# iostm32f205zx register map
Registers are 32-bit, access not given, no defined reset value unless marked. A register's access mark holds for its fields unless they carry their own. Addresses are absolute; registers are grouped by the start of their names; [hi:lo] are bit positions; {n}, {i} and the like mark numbered series; 'fields as' and 'values as' point back to an identical list.

## OTG
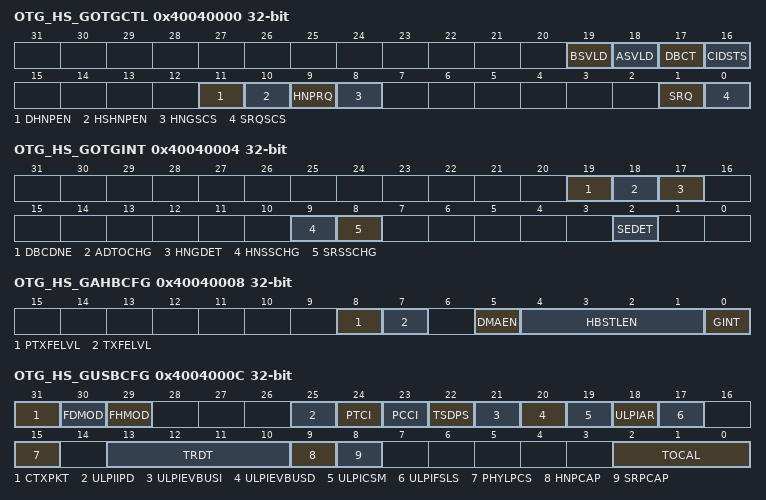
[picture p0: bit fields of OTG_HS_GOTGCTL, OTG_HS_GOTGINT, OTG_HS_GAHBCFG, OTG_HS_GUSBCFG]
0x40040000 OTG_HS_GOTGCTL
  [19] BSVLD, [18] ASVLD, [17] DBCT, [16] CIDSTS, [11] DHNPEN, [10] HSHNPEN, [9] HNPRQ, [8] HNGSCS, [1] SRQ, [0] SRQSCS
0x40040004 OTG_HS_GOTGINT
  [19] DBCDNE, [18] ADTOCHG, [17] HNGDET, [9] HNSSCHG, [8] SRSSCHG, [2] SEDET
0x40040008 OTG_HS_GAHBCFG
  [8] PTXFELVL, [7] TXFELVL, [5] DMAEN, [4:1] HBSTLEN, [0] GINT
0x4004000C OTG_HS_GUSBCFG
  [31] CTXPKT, [30] FDMOD, [29] FHMOD, [25] ULPIIPD, [24] PTCI, [23] PCCI, [22] TSDPS, [21] ULPIEVBUSI, [20] ULPIEVBUSD, [19] ULPICSM, [18] ULPIAR, [17] ULPIFSLS, [15] PHYLPCS, [13:10] TRDT, [9] HNPCAP, [8] SRPCAP, [2:0] TOCAL
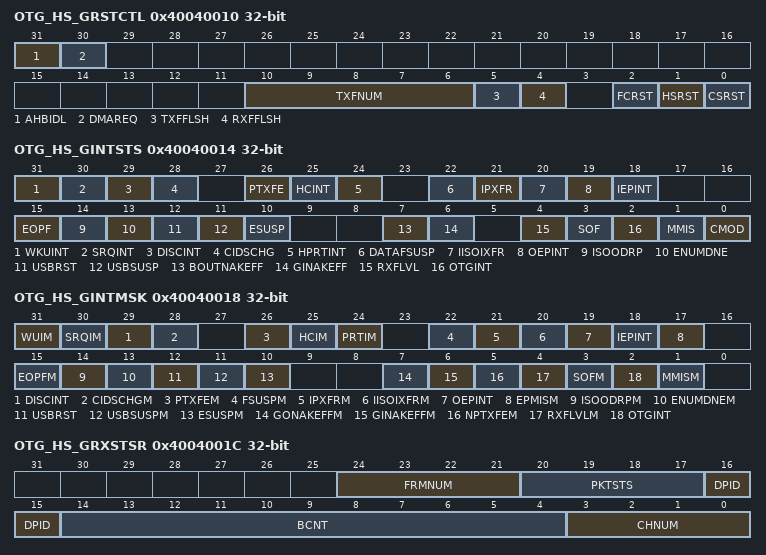
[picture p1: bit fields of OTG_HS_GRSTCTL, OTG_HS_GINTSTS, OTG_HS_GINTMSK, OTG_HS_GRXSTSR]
0x40040010 OTG_HS_GRSTCTL
  [31] AHBIDL, [30] DMAREQ, [10:6] TXFNUM, [5] TXFFLSH, [4] RXFFLSH, [2] FCRST, [1] HSRST, [0] CSRST
0x40040014 OTG_HS_GINTSTS
  [31] WKUINT, [30] SRQINT, [29] DISCINT, [28] CIDSCHG, [26] PTXFE, [25] HCINT, [24] HPRTINT, [22] DATAFSUSP, [21] IPXFR, [20] IISOIXFR, [19] OEPINT, [18] IEPINT, [15] EOPF, [14] ISOODRP, [13] ENUMDNE, [12] USBRST, [11] USBSUSP, [10] ESUSP, [7] BOUTNAKEFF, [6] GINAKEFF, [4] RXFLVL, [3] SOF, [2] OTGINT, [1] MMIS, [0] CMOD
0x40040018 OTG_HS_GINTMSK
  [31] WUIM, [30] SRQIM, [29] DISCINT, [28] CIDSCHGM, [26] PTXFEM, [25] HCIM, [24] PRTIM, [22] FSUSPM, [21] IPXFRM, [20] IISOIXFRM, [19] OEPINT, [18] IEPINT, [17] EPMISM, [15] EOPFM, [14] ISOODRPM, [13] ENUMDNEM, [12] USBRST, [11] USBSUSPM, [10] ESUSPM, [7] GONAKEFFM, [6] GINAKEFFM, [5] NPTXFEM, [4] RXFLVLM, [3] SOFM, [2] OTGINT, [1] MMISM
0x4004001C OTG_HS_GRXSTSR
  [24:21] FRMNUM, [20:17] PKTSTS, [16:15] DPID, [14:4] BCNT, [3:0] CHNUM
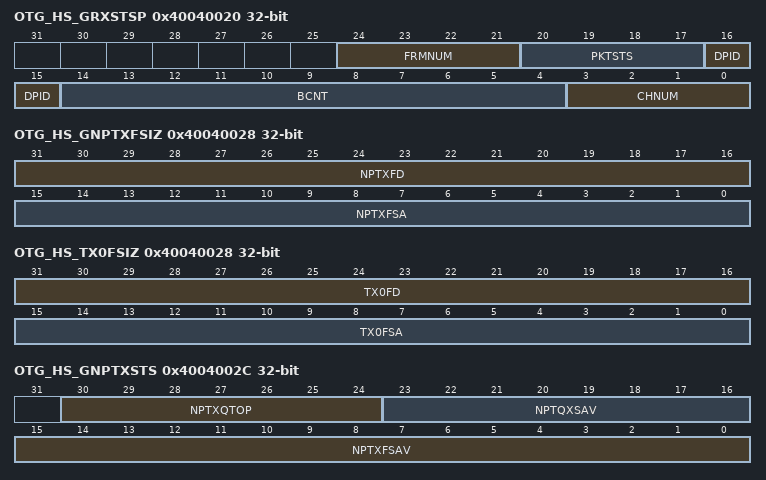
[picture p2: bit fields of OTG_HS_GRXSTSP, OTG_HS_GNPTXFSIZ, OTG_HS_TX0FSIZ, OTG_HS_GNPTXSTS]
0x40040020 OTG_HS_GRXSTSP
  fields as OTG_HS_GRXSTSR
0x40040024 OTG_HS_GRXFSIZ
  [15:0] RXFD
0x40040028 OTG_HS_GNPTXFSIZ
  [31:16] NPTXFD, [15:0] NPTXFSA
0x40040028 OTG_HS_TX0FSIZ
  [31:16] TX0FD, [15:0] TX0FSA
0x4004002C OTG_HS_GNPTXSTS
  [30:24] NPTXQTOP, [23:16] NPTQXSAV, [15:0] NPTXFSAV
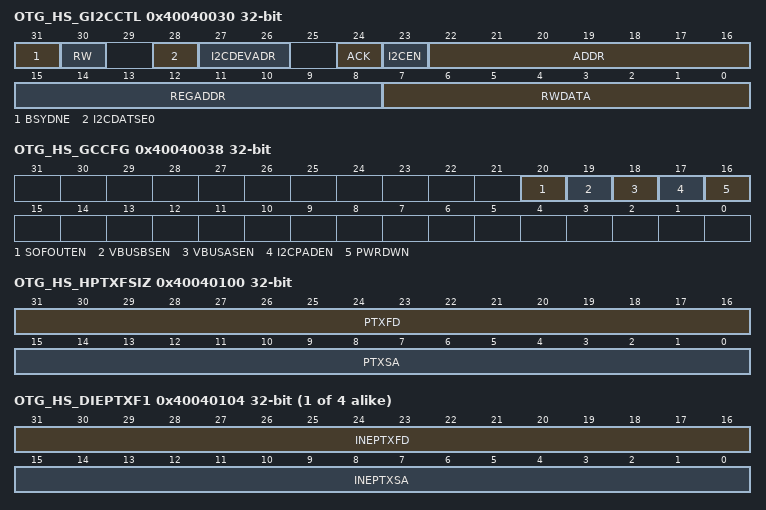
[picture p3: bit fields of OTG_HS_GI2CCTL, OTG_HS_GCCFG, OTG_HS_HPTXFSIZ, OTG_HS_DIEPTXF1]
0x40040030 OTG_HS_GI2CCTL
  [31] BSYDNE, [30] RW, [28] I2CDATSE0, [27:26] I2CDEVADR, [24] ACK, [23] I2CEN, [22:16] ADDR, [15:8] REGADDR, [7:0] RWDATA
0x40040038 OTG_HS_GCCFG
  [20] SOFOUTEN, [19] VBUSBSEN, [18] VBUSASEN, [17] I2CPADEN, [16] PWRDWN
0x4004003C OTG_HS_CID
0x40040100 OTG_HS_HPTXFSIZ
  [31:16] PTXFD, [15:0] PTXSA
{0x40040100+4i} OTG_HS_DIEPTXF{i} (i=1..4)
  [31:16] INEPTXFD, [15:0] INEPTXSA
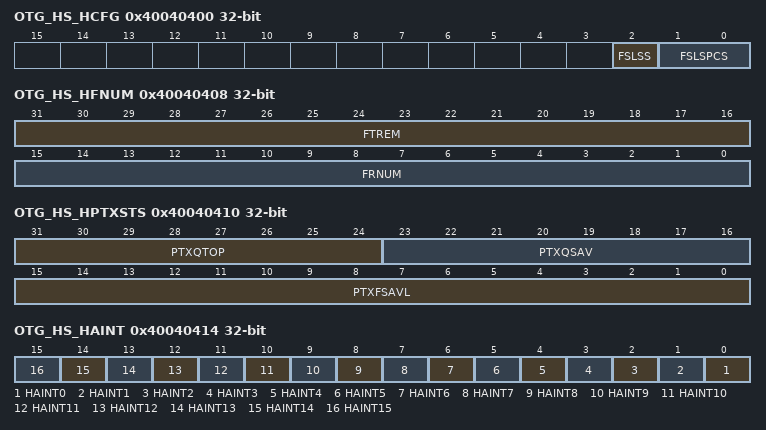
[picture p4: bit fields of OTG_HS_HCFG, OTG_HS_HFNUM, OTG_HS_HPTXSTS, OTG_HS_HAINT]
0x40040400 OTG_HS_HCFG
  [2] FSLSS, [1:0] FSLSPCS
0x40040404 OTG_HS_HFIR
  [15:0] FRIVL
0x40040408 OTG_HS_HFNUM
  [31:16] FTREM, [15:0] FRNUM
0x40040410 OTG_HS_HPTXSTS
  [31:24] PTXQTOP, [23:16] PTXQSAV, [15:0] PTXFSAVL
0x40040414 OTG_HS_HAINT
  [n] HAINT{n} (n=0..15)
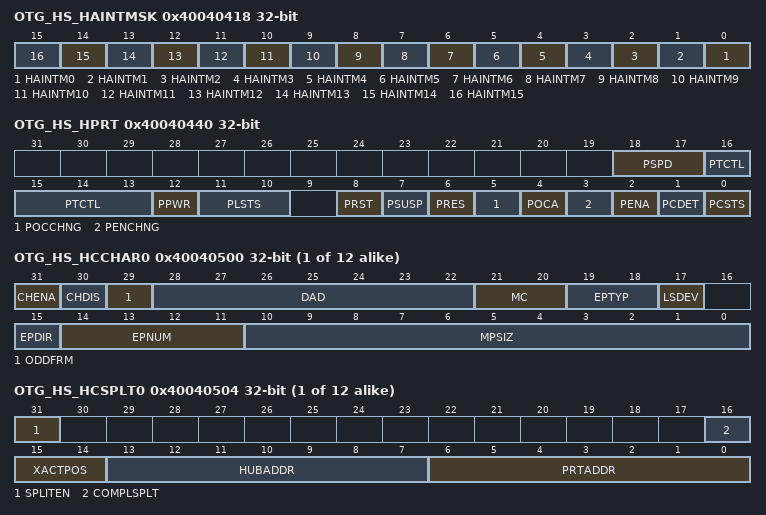
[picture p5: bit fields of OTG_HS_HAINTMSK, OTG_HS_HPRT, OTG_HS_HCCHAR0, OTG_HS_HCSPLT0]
0x40040418 OTG_HS_HAINTMSK
  [n] HAINTM{n} (n=0..15)
0x40040440 OTG_HS_HPRT
  [18:17] PSPD, [16:13] PTCTL, [12] PPWR, [11:10] PLSTS, [8] PRST, [7] PSUSP, [6] PRES, [5] POCCHNG, [4] POCA, [3] PENCHNG, [2] PENA, [1] PCDET, [0] PCSTS
{0x40040500+0x20*i} OTG_HS_HCCHAR{i} (i=0..11)
  [31] CHENA, [30] CHDIS, [29] ODDFRM, [28:22] DAD, [21:20] MC, [19:18] EPTYP, [17] LSDEV, [15] EPDIR, [14:11] EPNUM, [10:0] MPSIZ
{0x40040504+0x20*i} OTG_HS_HCSPLT{i} (i=0..11)
  [31] SPLITEN, [16] COMPLSPLT, [15:14] XACTPOS, [13:7] HUBADDR, [6:0] PRTADDR
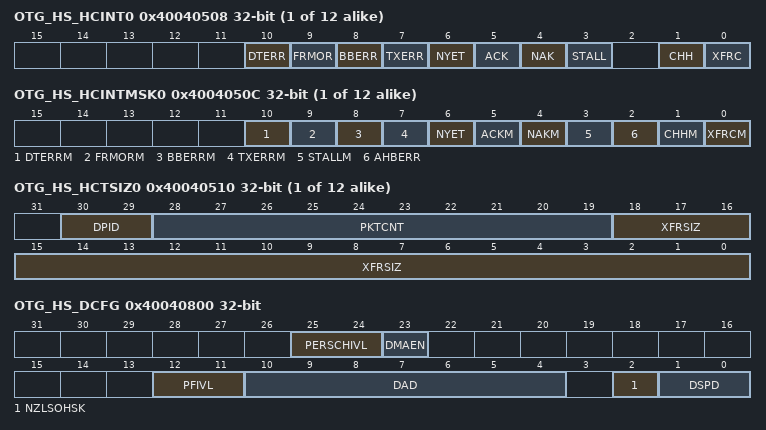
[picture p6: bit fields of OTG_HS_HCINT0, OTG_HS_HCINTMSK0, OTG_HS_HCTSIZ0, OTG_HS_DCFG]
{0x40040508+0x20*i} OTG_HS_HCINT{i} (i=0..11)
  [10] DTERR, [9] FRMOR, [8] BBERR, [7] TXERR, [6] NYET, [5] ACK, [4] NAK, [3] STALL, [1] CHH, [0] XFRC
{0x4004050C+0x20*i} OTG_HS_HCINTMSK{i} (i=0..11)
  [10] DTERRM, [9] FRMORM, [8] BBERRM, [7] TXERRM, [6] NYET, [5] ACKM, [4] NAKM, [3] STALLM, [2] AHBERR, [1] CHHM, [0] XFRCM
{0x40040510+0x20*i} OTG_HS_HCTSIZ{i} (i=0..11)
  [30:29] DPID, [28:19] PKTCNT, [18:0] XFRSIZ
{0x40040514+0x20*i} OTG_HS_HCDMA{i} (i=0..11)
0x40040800 OTG_HS_DCFG
  [25:24] PERSCHIVL, [23] DMAEN, [12:11] PFIVL, [10:4] DAD, [2] NZLSOHSK, [1:0] DSPD
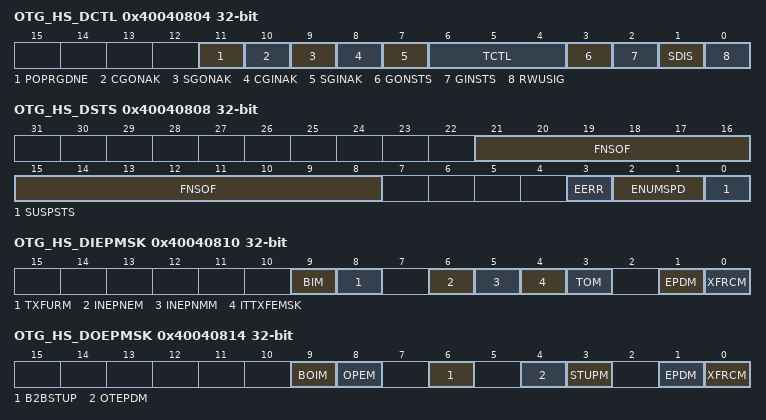
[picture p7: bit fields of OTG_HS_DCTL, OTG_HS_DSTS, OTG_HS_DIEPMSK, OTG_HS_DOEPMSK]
0x40040804 OTG_HS_DCTL
  [11] POPRGDNE, [10] CGONAK, [9] SGONAK, [8] CGINAK, [7] SGINAK, [6:4] TCTL, [3] GONSTS, [2] GINSTS, [1] SDIS, [0] RWUSIG
0x40040808 OTG_HS_DSTS
  [21:8] FNSOF, [3] EERR, [2:1] ENUMSPD, [0] SUSPSTS
0x40040810 OTG_HS_DIEPMSK
  [9] BIM, [8] TXFURM, [6] INEPNEM, [5] INEPNMM, [4] ITTXFEMSK, [3] TOM, [1] EPDM, [0] XFRCM
0x40040814 OTG_HS_DOEPMSK
  [9] BOIM, [8] OPEM, [6] B2BSTUP, [4] OTEPDM, [3] STUPM, [1] EPDM, [0] XFRCM
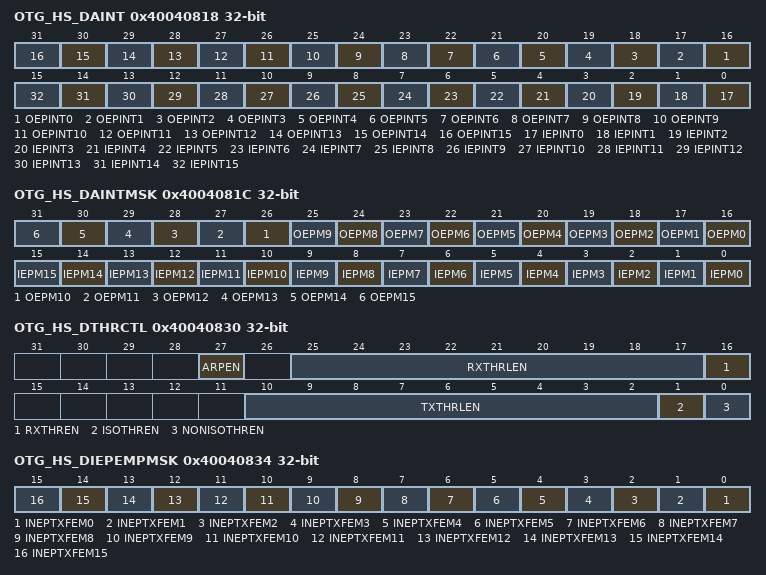
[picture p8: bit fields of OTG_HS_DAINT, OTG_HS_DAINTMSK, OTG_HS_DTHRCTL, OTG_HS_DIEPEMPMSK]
0x40040818 OTG_HS_DAINT
  [n+16] OEPINT{n} (n=0..15), [n] IEPINT{n} (n=0..15)
0x4004081C OTG_HS_DAINTMSK
  [n+16] OEPM{n} (n=0..15), [n] IEPM{n} (n=0..15)
0x40040828 OTG_HS_DVBUSDIS
  [15:0] VBUSDT
0x4004082C OTG_HS_DVBUSPULSE
  [11:0] DVBUSP
0x40040830 OTG_HS_DTHRCTL
  [27] ARPEN, [25:17] RXTHRLEN, [16] RXTHREN, [10:2] TXTHRLEN, [1] ISOTHREN, [0] NONISOTHREN
0x40040834 OTG_HS_DIEPEMPMSK
  [n] INEPTXFEM{n} (n=0..15)
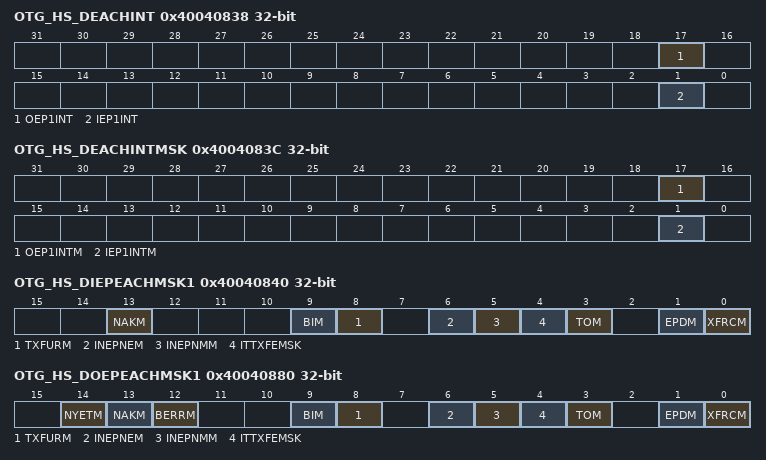
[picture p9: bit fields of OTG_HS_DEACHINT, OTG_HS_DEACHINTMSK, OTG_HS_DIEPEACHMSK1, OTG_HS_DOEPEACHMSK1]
0x40040838 OTG_HS_DEACHINT
  [17] OEP1INT, [1] IEP1INT
0x4004083C OTG_HS_DEACHINTMSK
  [17] OEP1INTM, [1] IEP1INTM
0x40040840 OTG_HS_DIEPEACHMSK1
  [13] NAKM, [9] BIM, [8] TXFURM, [6] INEPNEM, [5] INEPNMM, [4] ITTXFEMSK, [3] TOM, [1] EPDM, [0] XFRCM
0x40040880 OTG_HS_DOEPEACHMSK1
  [14] NYETM, [13] NAKM, [12] BERRM, [9] BIM, [8] TXFURM, [6] INEPNEM, [5] INEPNMM, [4] ITTXFEMSK, [3] TOM, [1] EPDM, [0] XFRCM
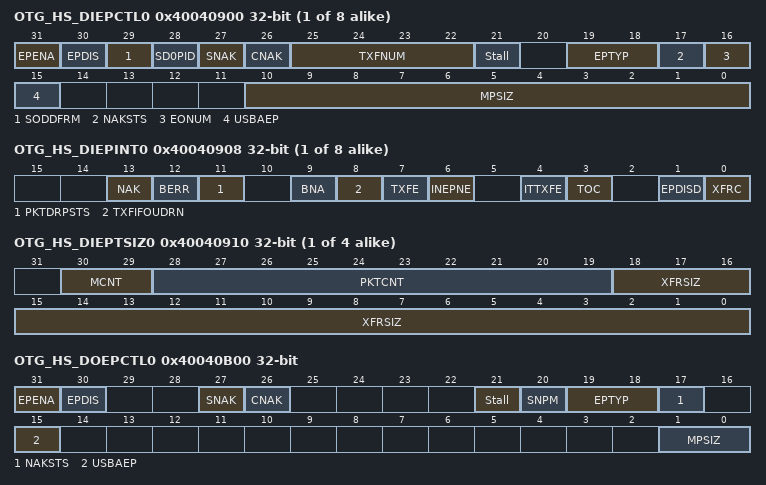
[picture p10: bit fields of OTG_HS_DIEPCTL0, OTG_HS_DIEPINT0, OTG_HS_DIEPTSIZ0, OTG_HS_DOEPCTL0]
{0x40040900+0x20*i} OTG_HS_DIEPCTL{i} (i=0..7)
  [31] EPENA, [30] EPDIS, [29] SODDFRM, [28] SD0PID, [27] SNAK, [26] CNAK, [25:22] TXFNUM, [21] Stall, [19:18] EPTYP, [17] NAKSTS, [16] EONUM, [15] USBAEP, [10:0] MPSIZ
{0x40040908+0x20*i} OTG_HS_DIEPINT{i} (i=0..7)
  [13] NAK, [12] BERR, [11] PKTDRPSTS, [9] BNA, [8] TXFIFOUDRN, [7] TXFE, [6] INEPNE, [4] ITTXFE, [3] TOC, [1] EPDISD, [0] XFRC
{0x40040910+0x20*i} OTG_HS_DIEPTSIZ{i} (i=0..3)
  [30:29] MCNT, [28:19] PKTCNT, [18:0] XFRSIZ
{0x40040914+0x20*i} OTG_HS_DIEPDMA{i} (i=0..3)
{0x40040918+0x20*i} OTG_HS_DTXFSTS{i} (i=0..3)
  [15:0] INEPTFSAV
{0x4004091C+0x20*i} OTG_HS_DIEPDMAB{i} (i=0..3)
0x40040B00 OTG_HS_DOEPCTL0
  [31] EPENA, [30] EPDIS, [27] SNAK, [26] CNAK, [21] Stall, [20] SNPM, [19:18] EPTYP, [17] NAKSTS, [15] USBAEP, [1:0] MPSIZ
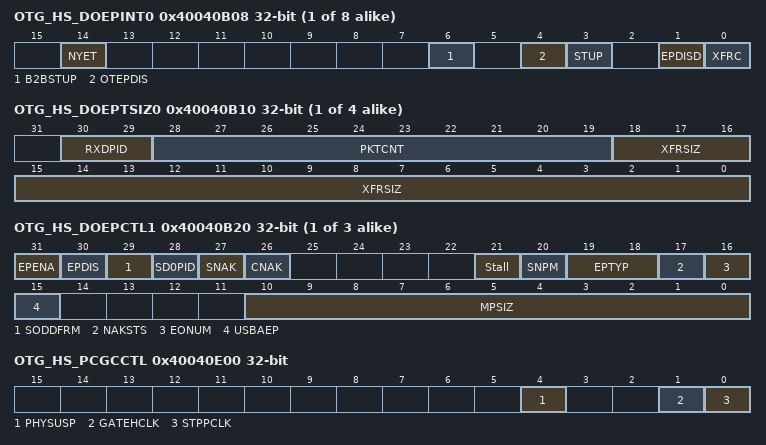
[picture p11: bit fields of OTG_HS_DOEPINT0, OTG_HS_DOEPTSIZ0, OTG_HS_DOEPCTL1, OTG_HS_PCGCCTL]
{0x40040B08+0x20*i} OTG_HS_DOEPINT{i} (i=0..7)
  [14] NYET, [6] B2BSTUP, [4] OTEPDIS, [3] STUP, [1] EPDISD, [0] XFRC
{0x40040B10+0x20*i} OTG_HS_DOEPTSIZ{i} (i=0..3)
  [30:29] RXDPID, [28:19] PKTCNT, [18:0] XFRSIZ
{0x40040B14+0x20*i} OTG_HS_DOEPDMA{i} (i=0..3)
{0x40040B1C+0x20*i} OTG_HS_DOEPDMAB{i} (i=0..3)
{0x40040B00+0x20*i} OTG_HS_DOEPCTL{i} (i=1..3)
  [31] EPENA, [30] EPDIS, [29] SODDFRM, [28] SD0PID, [27] SNAK, [26] CNAK, [21] Stall, [20] SNPM, [19:18] EPTYP, [17] NAKSTS, [16] EONUM, [15] USBAEP, [10:0] MPSIZ
0x40040E00 OTG_HS_PCGCCTL
  [4] PHYSUSP, [1] GATEHCLK, [0] STPPCLK
